# ExampleDevice register map
Vendor: OpenSource; Series: RV32Sim; File version: 1.0
Example Device SVD for RV32Sim
Registers are 32-bit, read-write, reset 0x0 unless marked. A register's access mark holds for its fields unless they carry their own. Offsets are from the block's base; lines under a group give offsets from that group; [hi:lo] are bit positions; {n}, {i} and the like mark numbered series; 'fields as' and 'values as' point back to an identical list; <NAME> marks a mode.

## Memory map
0x40000000 UART0 — Universal Asynchronous Receiver/Transmitter

## UART0 — Universal Asynchronous Receiver/Transmitter
Base 0x40000000
0x00 DATA
  [7:0] VAL
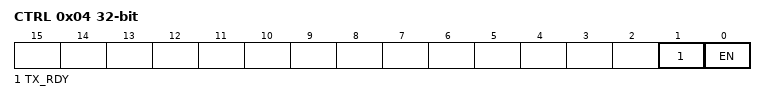
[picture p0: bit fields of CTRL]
0x04 CTRL
  [1] TX_RDY
  [0] EN — Enable UART
